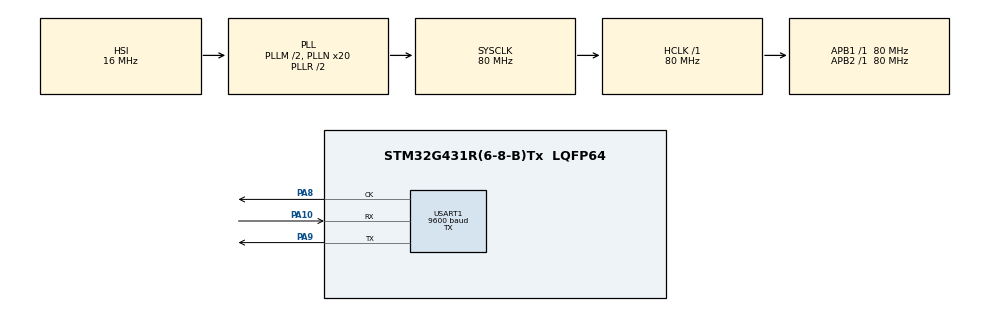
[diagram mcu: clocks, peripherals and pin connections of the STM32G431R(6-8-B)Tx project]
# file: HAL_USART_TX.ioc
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Mcu.Family=STM32G4
Mcu.Name=STM32G431R(6-8-B)Tx
Mcu.Package=LQFP64
NVIC.PriorityGroup=NVIC_PRIORITYGROUP_4
PA10.Mode=Synchronous
PA10.Signal=USART1_RX
PA8.Mode=Synchronous
PA8.Signal=USART1_CK
PA9.Mode=Synchronous
PA9.Signal=USART1_TX
PF0-OSC_IN.Mode=HSE-External-Oscillator
PF0-OSC_IN.Signal=RCC_OSC_IN
PF1-OSC_OUT.Mode=HSE-External-Oscillator
PF1-OSC_OUT.Signal=RCC_OSC_OUT
ProjectManager.HeapSize=0x200
ProjectManager.StackSize=0x400
ProjectManager.TargetToolchain=MDK-ARM V5.27
RCC.ADC12Freq_Value=80000000
RCC.AHBFreq_Value=80000000
RCC.APB1Freq_Value=80000000
RCC.APB1TimFreq_Value=80000000
RCC.APB2Freq_Value=80000000
RCC.APB2TimFreq_Value=80000000
RCC.CortexFreq_Value=80000000
RCC.EXTERNAL_CLOCK_VALUE=12288000
RCC.HCLKFreq_Value=80000000
RCC.HSE_VALUE=24000000
RCC.HSI48_VALUE=48000000
RCC.HSI_VALUE=16000000
RCC.LSE_VALUE=32768
RCC.PLLM=RCC_PLLM_DIV2
RCC.PLLN=20
RCC.SYSCLKFreq_VALUE=80000000
RCC.SYSCLKSource=RCC_SYSCLKSOURCE_PLLCLK
RCC.USBFreq_Value=80000000
RCC.VCOOutputFreq_Value=160000000
USART1.BaudRate=9600
USART1.Mode=MODE_TX
USART1.VirtualMode-Synchronous=VM_SYNC
VP_SYS_VS_DBSignals.Mode=DisableDeadBatterySignals
board=custom

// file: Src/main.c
/* USER CODE BEGIN Header */
/**
  ******************************************************************************
  * @file           : main.c
  * @brief          : Main program body
  ******************************************************************************
  * @attention
  *
  * <h2><center>&copy; Copyright (c) 2020 STMicroelectronics.
  * All rights reserved.</center></h2>
  *
  * This software component is licensed by ST under BSD 3-Clause license,
  * the "License"; You may not use this file except in compliance with the
  * License. You may obtain a copy of the License at:
  *                        opensource.org/licenses/BSD-3-Clause
  *
  ******************************************************************************
  */
/* USER CODE END Header */

#include "main.h"
#include "stdio.h"
#include "string.h"

USART_HandleTypeDef husart1;

void SystemClock_Config(void);
static void MX_GPIO_Init(void);
static void MX_USART1_Init(void);

int main(void)
{
  /* USER CODE BEGIN 1 */

	int counter = 0;
	char str[40];

  /* USER CODE END 1 */

  /* MCU Configuration--------------------------------------------------------*/

  /* Reset of all peripherals, Initializes the Flash interface and the Systick. */
  HAL_Init();

  /* Configure the system clock */
  SystemClock_Config();

  /* Initialize all configured peripherals */
  MX_GPIO_Init();
  MX_USART1_Init();

  /* Infinite loop */
  /* USER CODE BEGIN WHILE */
  while (1)
  {
		sprintf(str, "%04d:Hello,world.\r\n", counter);
		HAL_USART_Transmit(&husart1,(unsigned char *)str, strlen(str), 50);
		HAL_Delay(500);

		if(++counter == 10000){
			counter = 0;
		}
  }
  /* USER CODE END 3 */
}

void SystemClock_Config(void)
{
  RCC_OscInitTypeDef RCC_OscInitStruct = {0};
  RCC_ClkInitTypeDef RCC_ClkInitStruct = {0};
  RCC_PeriphCLKInitTypeDef PeriphClkInit = {0};

  /** Configure the main internal regulator output voltage
  */
  HAL_PWREx_ControlVoltageScaling(PWR_REGULATOR_VOLTAGE_SCALE1);
  /** Initializes the CPU, AHB and APB busses clocks
  */
  RCC_OscInitStruct.OscillatorType = RCC_OSCILLATORTYPE_HSI;
  RCC_OscInitStruct.HSIState = RCC_HSI_ON;
  RCC_OscInitStruct.HSICalibrationValue = RCC_HSICALIBRATION_DEFAULT;
  RCC_OscInitStruct.PLL.PLLState = RCC_PLL_ON;
  RCC_OscInitStruct.PLL.PLLSource = RCC_PLLSOURCE_HSI;
  RCC_OscInitStruct.PLL.PLLM = RCC_PLLM_DIV2;
  RCC_OscInitStruct.PLL.PLLN = 20;
  RCC_OscInitStruct.PLL.PLLP = RCC_PLLP_DIV2;
  RCC_OscInitStruct.PLL.PLLQ = RCC_PLLQ_DIV2;
  RCC_OscInitStruct.PLL.PLLR = RCC_PLLR_DIV2;
  if (HAL_RCC_OscConfig(&RCC_OscInitStruct) != HAL_OK)
  {
    Error_Handler();
  }
  /** Initializes the CPU, AHB and APB busses clocks
  */
  RCC_ClkInitStruct.ClockType = RCC_CLOCKTYPE_HCLK|RCC_CLOCKTYPE_SYSCLK
                              |RCC_CLOCKTYPE_PCLK1|RCC_CLOCKTYPE_PCLK2;
  RCC_ClkInitStruct.SYSCLKSource = RCC_SYSCLKSOURCE_PLLCLK;
  RCC_ClkInitStruct.AHBCLKDivider = RCC_SYSCLK_DIV1;
  RCC_ClkInitStruct.APB1CLKDivider = RCC_HCLK_DIV1;
  RCC_ClkInitStruct.APB2CLKDivider = RCC_HCLK_DIV1;

  if (HAL_RCC_ClockConfig(&RCC_ClkInitStruct, FLASH_LATENCY_3) != HAL_OK)
  {
    Error_Handler();
  }
  /** Initializes the peripherals clocks
  */
  PeriphClkInit.PeriphClockSelection = RCC_PERIPHCLK_USART1;
  PeriphClkInit.Usart1ClockSelection = RCC_USART1CLKSOURCE_PCLK2;
  if (HAL_RCCEx_PeriphCLKConfig(&PeriphClkInit) != HAL_OK)
  {
    Error_Handler();
  }
}

static void MX_USART1_Init(void)
{

  husart1.Instance = USART1;
  husart1.Init.BaudRate = 9600;
  husart1.Init.WordLength = USART_WORDLENGTH_8B;
  husart1.Init.StopBits = USART_STOPBITS_1;
  husart1.Init.Parity = USART_PARITY_NONE;
  husart1.Init.Mode = USART_MODE_TX;
  husart1.Init.CLKPolarity = USART_POLARITY_LOW;
  husart1.Init.CLKPhase = USART_PHASE_1EDGE;
  husart1.Init.CLKLastBit = USART_LASTBIT_DISABLE;
  husart1.Init.ClockPrescaler = USART_PRESCALER_DIV1;
  husart1.SlaveMode = USART_SLAVEMODE_DISABLE;
  if (HAL_USART_Init(&husart1) != HAL_OK)
  {
    Error_Handler();
  }
  if (HAL_USARTEx_SetTxFifoThreshold(&husart1, USART_TXFIFO_THRESHOLD_1_8) != HAL_OK)
  {
    Error_Handler();
  }
  if (HAL_USARTEx_SetRxFifoThreshold(&husart1, USART_RXFIFO_THRESHOLD_1_8) != HAL_OK)
  {
    Error_Handler();
  }
  if (HAL_USARTEx_DisableFifoMode(&husart1) != HAL_OK)
  {
    Error_Handler();
  }

}

static void MX_GPIO_Init(void)
{

  /* GPIO Ports Clock Enable */
  __HAL_RCC_GPIOF_CLK_ENABLE();
  __HAL_RCC_GPIOA_CLK_ENABLE();

}

void Error_Handler(void)
{
}

/************************ (C) COPYRIGHT STMicroelectronics *****END OF FILE****/
